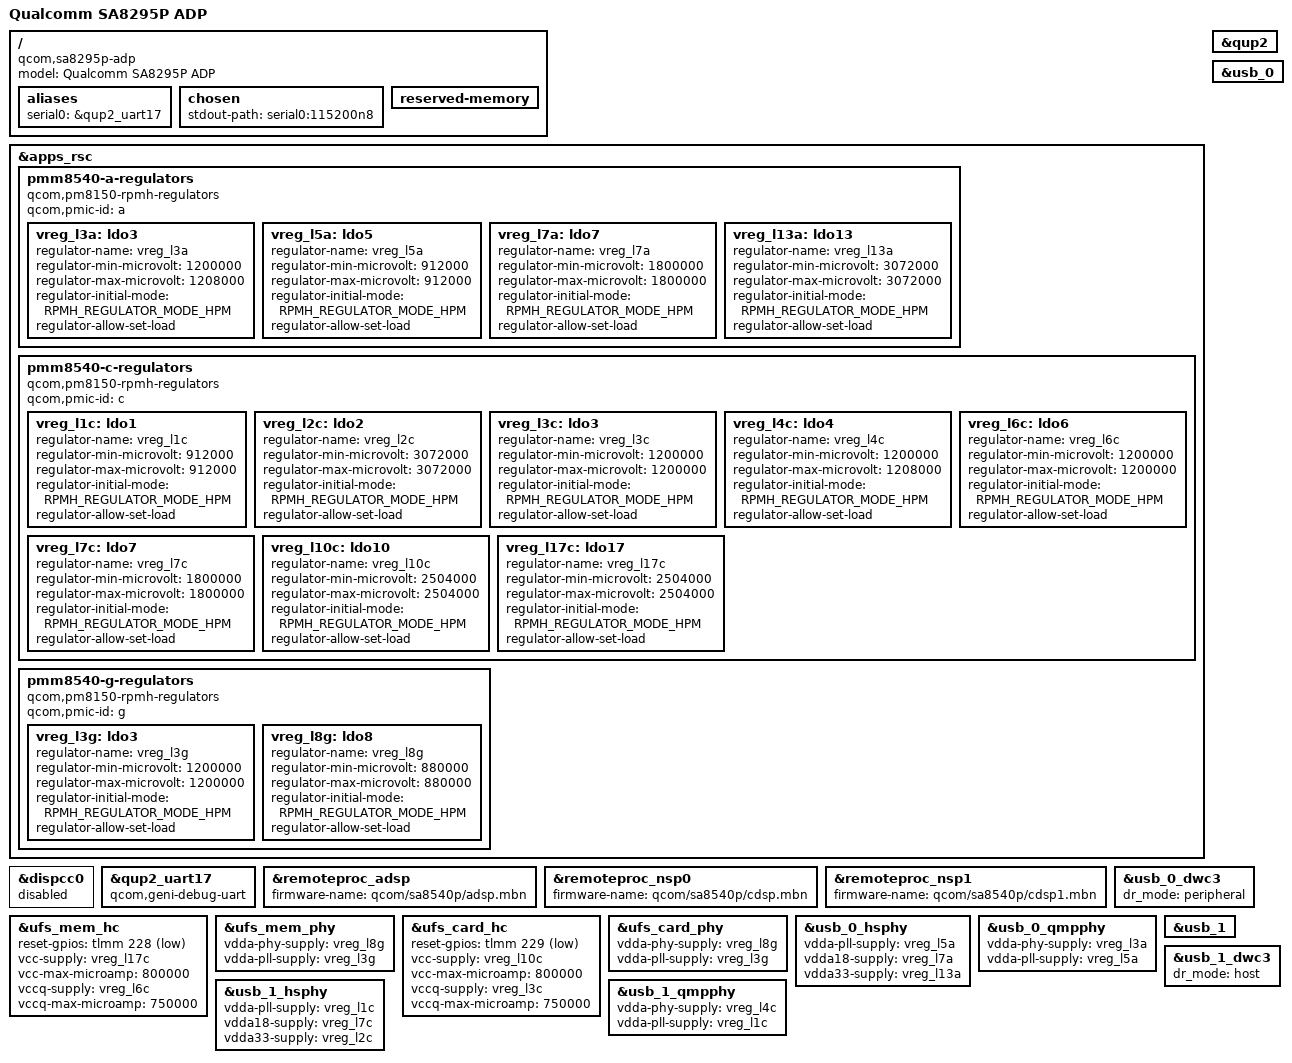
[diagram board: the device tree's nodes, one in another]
// SPDX-License-Identifier: BSD-3-Clause
/*
 * Copyright (c) 2017-2019, The Linux Foundation. All rights reserved.
 * Copyright (c) 2020-2021, Linaro Limited
 */

/dts-v1/;

#include <dt-bindings/gpio/gpio.h>
#include <dt-bindings/input/gpio-keys.h>
#include <dt-bindings/input/input.h>
#include <dt-bindings/regulator/qcom,rpmh-regulator.h>

#include "sa8540p.dtsi"

/ {
	model = "Qualcomm SA8295P ADP";
	compatible = "qcom,sa8295p-adp", "qcom,sa8540p";

	aliases {
		serial0 = &qup2_uart17;
	};

	chosen {
		stdout-path = "serial0:115200n8";
	};

	reserved-memory {
	};
};

&apps_rsc {
	pmm8540-a-regulators {
		compatible = "qcom,pm8150-rpmh-regulators";
		qcom,pmic-id = "a";

		vreg_l3a: ldo3 {
			regulator-name = "vreg_l3a";
			regulator-min-microvolt = <1200000>;
			regulator-max-microvolt = <1208000>;
			regulator-initial-mode = <RPMH_REGULATOR_MODE_HPM>;
			regulator-allow-set-load;
		};

		vreg_l5a: ldo5 {
			regulator-name = "vreg_l5a";
			regulator-min-microvolt = <912000>;
			regulator-max-microvolt = <912000>;
			regulator-initial-mode = <RPMH_REGULATOR_MODE_HPM>;
			regulator-allow-set-load;
		};

		vreg_l7a: ldo7 {
			regulator-name = "vreg_l7a";
			regulator-min-microvolt = <1800000>;
			regulator-max-microvolt = <1800000>;
			regulator-initial-mode = <RPMH_REGULATOR_MODE_HPM>;
			regulator-allow-set-load;
		};

		vreg_l13a: ldo13 {
			regulator-name = "vreg_l13a";
			regulator-min-microvolt = <3072000>;
			regulator-max-microvolt = <3072000>;
			regulator-initial-mode = <RPMH_REGULATOR_MODE_HPM>;
			regulator-allow-set-load;
		};
	};

	pmm8540-c-regulators {
		compatible = "qcom,pm8150-rpmh-regulators";
		qcom,pmic-id = "c";

		vreg_l1c: ldo1 {
			regulator-name = "vreg_l1c";
			regulator-min-microvolt = <912000>;
			regulator-max-microvolt = <912000>;
			regulator-initial-mode = <RPMH_REGULATOR_MODE_HPM>;
			regulator-allow-set-load;
		};

		vreg_l2c: ldo2 {
			regulator-name = "vreg_l2c";
			regulator-min-microvolt = <3072000>;
			regulator-max-microvolt = <3072000>;
			regulator-initial-mode = <RPMH_REGULATOR_MODE_HPM>;
			regulator-allow-set-load;
		};

		vreg_l3c: ldo3 {
			regulator-name = "vreg_l3c";
			regulator-min-microvolt = <1200000>;
			regulator-max-microvolt = <1200000>;
			regulator-initial-mode = <RPMH_REGULATOR_MODE_HPM>;
			regulator-allow-set-load;
		};

		vreg_l4c: ldo4 {
			regulator-name = "vreg_l4c";
			regulator-min-microvolt = <1200000>;
			regulator-max-microvolt = <1208000>;
			regulator-initial-mode = <RPMH_REGULATOR_MODE_HPM>;
			regulator-allow-set-load;
		};

		vreg_l6c: ldo6 {
			regulator-name = "vreg_l6c";
			regulator-min-microvolt = <1200000>;
			regulator-max-microvolt = <1200000>;
			regulator-initial-mode = <RPMH_REGULATOR_MODE_HPM>;
			regulator-allow-set-load;
		};

		vreg_l7c: ldo7 {
			regulator-name = "vreg_l7c";
			regulator-min-microvolt = <1800000>;
			regulator-max-microvolt = <1800000>;
			regulator-initial-mode = <RPMH_REGULATOR_MODE_HPM>;
			regulator-allow-set-load;
		};

		vreg_l10c: ldo10 {
			regulator-name = "vreg_l10c";
			regulator-min-microvolt = <2504000>;
			regulator-max-microvolt = <2504000>;
			regulator-initial-mode = <RPMH_REGULATOR_MODE_HPM>;
			regulator-allow-set-load;
		};

		vreg_l17c: ldo17 {
			regulator-name = "vreg_l17c";
			regulator-min-microvolt = <2504000>;
			regulator-max-microvolt = <2504000>;
			regulator-initial-mode = <RPMH_REGULATOR_MODE_HPM>;
			regulator-allow-set-load;
		};
	};

	pmm8540-g-regulators {
		compatible = "qcom,pm8150-rpmh-regulators";
		qcom,pmic-id = "g";

		vreg_l3g: ldo3 {
			regulator-name = "vreg_l3g";
			regulator-min-microvolt = <1200000>;
			regulator-max-microvolt = <1200000>;
			regulator-initial-mode = <RPMH_REGULATOR_MODE_HPM>;
			regulator-allow-set-load;
		};

		vreg_l8g: ldo8 {
			regulator-name = "vreg_l8g";
			regulator-min-microvolt = <880000>;
			regulator-max-microvolt = <880000>;
			regulator-initial-mode = <RPMH_REGULATOR_MODE_HPM>;
			regulator-allow-set-load;
		};
	};
};

&dispcc0 {
	status = "disabled";
};

&qup2 {
	status = "okay";
};

&qup2_uart17 {
	compatible = "qcom,geni-debug-uart";
	status = "okay";
};

&remoteproc_adsp {
	status = "okay";
	firmware-name = "qcom/sa8540p/adsp.mbn";
};

&remoteproc_nsp0 {
	status = "okay";
	firmware-name = "qcom/sa8540p/cdsp.mbn";
};

&remoteproc_nsp1 {
	status = "okay";
	firmware-name = "qcom/sa8540p/cdsp1.mbn";
};

&ufs_mem_hc {
	status = "okay";

	reset-gpios = <&tlmm 228 GPIO_ACTIVE_LOW>;

	vcc-supply = <&vreg_l17c>;
	vcc-max-microamp = <800000>;
	vccq-supply = <&vreg_l6c>;
	vccq-max-microamp = <750000>;
};

&ufs_mem_phy {
	status = "okay";

	vdda-phy-supply = <&vreg_l8g>;
	vdda-pll-supply = <&vreg_l3g>;
};

&ufs_card_hc {
	status = "okay";

	reset-gpios = <&tlmm 229 GPIO_ACTIVE_LOW>;

	vcc-supply = <&vreg_l10c>;
	vcc-max-microamp = <800000>;
	vccq-supply = <&vreg_l3c>;
	vccq-max-microamp = <750000>;
};

&ufs_card_phy {
	status = "okay";

	vdda-phy-supply = <&vreg_l8g>;
	vdda-pll-supply = <&vreg_l3g>;
};

&usb_0 {
	status = "okay";
};

&usb_0_dwc3 {
	/* TODO: Define USB-C connector properly */
	dr_mode = "peripheral";
};

&usb_0_hsphy {
	status = "okay";

	vdda-pll-supply = <&vreg_l5a>;
	vdda18-supply = <&vreg_l7a>;
	vdda33-supply = <&vreg_l13a>;
};

&usb_0_qmpphy {
	status = "okay";

	vdda-phy-supply = <&vreg_l3a>;
	vdda-pll-supply = <&vreg_l5a>;
};

&usb_1 {
	status = "okay";
};

&usb_1_dwc3 {
	/* TODO: Define USB-C connector properly */
	dr_mode = "host";
};

&usb_1_hsphy {
	status = "okay";

	vdda-pll-supply = <&vreg_l1c>;
	vdda18-supply = <&vreg_l7c>;
	vdda33-supply = <&vreg_l2c>;
};

&usb_1_qmpphy {
	status = "okay";

	vdda-phy-supply = <&vreg_l4c>;
	vdda-pll-supply = <&vreg_l1c>;
};
